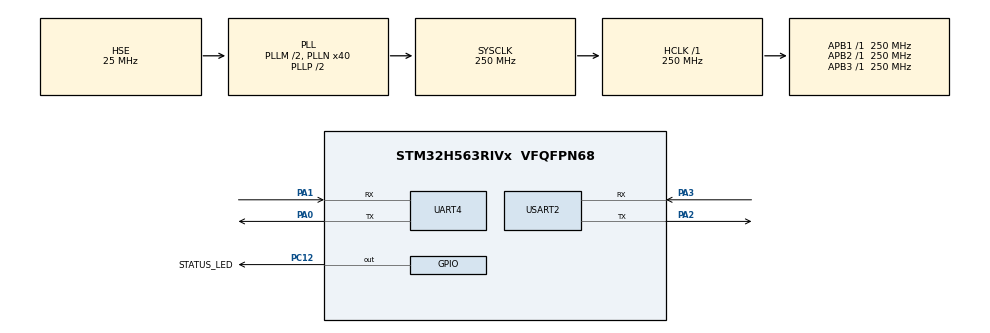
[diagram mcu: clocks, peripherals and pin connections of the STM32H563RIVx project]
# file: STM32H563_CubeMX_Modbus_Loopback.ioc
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BOOTPATH.BootPathName=LEGACY
BOOTPATH.UserSelectedBootPath=LEGACY
CORTEX_M33_NS.MPU_Control.Ext=__NULL
CORTEX_M33_NS.userName=CORTEX_M33
DCACHE1.DCACHE_Read_Burst_Type.Ext=DCACHE_READ_BURST_WRAP
DCACHE1.Instance.Ext=DCACHE$Index
Extended=true
Mcu.Family=STM32H5
Mcu.Name=STM32H563RIVx
Mcu.Package=VFQFPN68
NVIC.PriorityGroup=NVIC_PRIORITYGROUP_4
NVIC.UART4_IRQn=true\:10\:0\:true\:false\:true\:true\:true\:true
NVIC.USART2_IRQn=true\:10\:0\:true\:false\:true\:true\:true\:true
PA0.Mode=Asynchronous
PA0.Signal=UART4_TX
PA1.Mode=Asynchronous
PA1.Signal=UART4_RX
PA2.Mode=Asynchronous
PA2.Signal=USART2_TX
PA3.Mode=Asynchronous
PA3.Signal=USART2_RX
PC12.GPIO_Label=STATUS_LED
PC12.Signal=GPIO_Output
PH0-OSC_IN(PH0).Mode=HSE-External-Oscillator
PH0-OSC_IN(PH0).Signal=RCC_OSC_IN
PH1-OSC_OUT(PH1).Mode=HSE-External-Oscillator
PH1-OSC_OUT(PH1).Signal=RCC_OSC_OUT
PWR.DisableDeadBatterySignalsConfig.Ext=Disable
PWR.pwrPrivilege.Ext=PWR_PRIVILEGE_NO
ProjectManager.HeapSize=0x200
ProjectManager.StackSize=0x400
ProjectManager.TargetToolchain=MDK-ARM V5.37
RCC.ADCCLockSelection.Ext=RCC_ADCDACCLKSOURCE_HCLK
RCC.ADCFreq_Value=250000000
RCC.AHBCLKDivider.Ext=RCC_SYSCLK_DIV1
RCC.AHBCLKDividerARG.Ext=RCC_SYSCLK_DIV1
RCC.AHBFreq_Value=250000000
RCC.APB1CLKDivider.Ext=RCC_HCLK_DIV1
RCC.APB1CLKDividerARG.Ext=RCC_HCLK_DIV1
RCC.APB1Freq_Value=250000000
RCC.APB1TimCLKDivider.Ext=1
RCC.APB1TimFreq_Value=250000000
RCC.APB2CLKDivider.Ext=RCC_HCLK_DIV1
RCC.APB2CLKDividerARG.Ext=RCC_HCLK_DIV1
RCC.APB2Freq_Value=250000000
RCC.APB2TimCLKDivider.Ext=1
RCC.APB2TimFreq_Value=250000000
RCC.APB3Freq_Value=250000000
RCC.CKPERSourceSelection.Ext=RCC_CLKPSOURCE_HSI
RCC.CSICalibrationValue=16
RCC.CSI_VALUE=4000000
RCC.ClockType.Ext=RCC_CLOCKTYPE_HCLK|RCC_CLOCKTYPE_SYSCLK|RCC_CLOCKTYPE_PCLK1|RCC_CLOCKTYPE_PCLK2|RCC_CLOCKTYPE_PCLK3
RCC.ClockTypeARG.Ext=RCC_CLOCKTYPE_HCLK|RCC_CLOCKTYPE_SYSCLK|RCC_CLOCKTYPE_PCLK1|RCC_CLOCKTYPE_PCLK2|RCC_CLOCKTYPE_PCLK3
RCC.ClockTypeHCLK.Ext=RCC_CLOCKTYPE_HCLK
RCC.ClockTypePCLK1.Ext=RCC_CLOCKTYPE_PCLK1
RCC.ClockTypePCLK2.Ext=RCC_CLOCKTYPE_PCLK2
RCC.ClockTypePCLK3.Ext=RCC_CLOCKTYPE_PCLK3
RCC.ClockTypeSysClk.Ext=RCC_CLOCKTYPE_SYSCLK
RCC.CortexFreq_Value=250000000
RCC.Cortex_Div.Ext=SYSTICK_CLKSOURCE_HCLK
RCC.EPOD_VALUE=25000000
RCC.EnableCSSLSE.Ext=false
RCC.EnbaleCSS.Ext=false
RCC.FLatency.Ext=FLASH_LATENCY_5
RCC.Flash_Delay.Ext=FLASH_PROGRAMMING_DELAY_2
RCC.HCLKFreq_Value=250000000
RCC.HSE_Timout.Ext=100
RCC.HSE_VALUE=25000000
RCC.HSI48_VALUE=48000000
RCC.HSICalibrationValue.Ext=64
RCC.HSI_VALUE=64000000
RCC.I2C1CLockSelection.Ext=RCC_I2C1CLKSOURCE_PCLK1
RCC.I2C2CLockSelection.Ext=RCC_I2C2CLKSOURCE_PCLK1
RCC.I2C3CLockSelection.Ext=RCC_I2C3CLKSOURCE_PCLK3
RCC.I3C1CLockSelection.Ext=RCC_I3C1CLKSOURCE_PCLK1
RCC.LPTIM1CLockSelection.Ext=RCC_LPTIM1CLKSOURCE_PCLK3
RCC.LPTIM2CLockSelection.Ext=RCC_LPTIM2CLKSOURCE_PCLK1
RCC.LPUART1CLockSelection.Ext=RCC_LPUART1CLKSOURCE_PCLK3
RCC.LSE_Timout.Ext=5000
RCC.LSE_VALUE=32768
RCC.LSIRC_VALUE=32000
RCC.OscillatorType.Ext=RCC_OSCILLATORTYPE_HSE
RCC.PLL1P.Ext=2
RCC.PLL1Q.Ext=2
RCC.PLL1R.Ext=2
RCC.PLL1_VCI_Range.Ext=RCC_PLL1_VCIRANGE_3
RCC.PLL2FRACN=0
RCC.PLL2M.Ext=1
RCC.PLL2P.Ext=2
RCC.PLL2Q.Ext=2
RCC.PLL2R.Ext=2
RCC.PLL2_VCI_Range.Ext=RCC_PLL2_VCIRANGE_3
RCC.PLL3FRACN=0
RCC.PLL3M.Ext=1
RCC.PLL3P.Ext=2
RCC.PLL3_VCI_Range.Ext=RCC_PLL3_VCIRANGE_3
RCC.PLLFRACN=0
RCC.PLLM=2
RCC.PLLN=40
RCC.PLLSourceVirtual=RCC_PLL1_SOURCE_HSE
RCC.PWR_Regulator_Voltage_Scale.Ext=PWR_REGULATOR_VOLTAGE_SCALE0
RCC.RCC_MCO1Source.Ext=RCC_MCO1SOURCE_HSI
RCC.RCC_MCO2Div.Ext=RCC_MCODIV_1
RCC.RCC_MCODiv.Ext=RCC_MCODIV_1
RCC.RCC_RTC_Clock_Source_FROM_HSE.Ext=RCC_RTC_HSE_NOCLOCK
RCC.RCC_TIM_PRescaler_Selection.Ext=RCC_TIMPRES_DESACTIVATED
RCC.RTCClockSelection.Ext=RCC_RTCCLKSOURCE_LSI
RCC.SAI1CLockSelection.Ext=RCC_SAI1CLKSOURCE_PLL2P
RCC.SAI2CLockSelection.Ext=RCC_SAI2CLKSOURCE_PLL2P
RCC.SDMMC1ClockSelection.Ext=RCC_SDMMC1CLKSOURCE_PLL1Q
RCC.SPI1CLockSelection.Ext=RCC_SPI1CLKSOURCE_PLL1Q
RCC.SPI2CLockSelection.Ext=RCC_SPI2CLKSOURCE_PLL1Q
RCC.SPI3CLockSelection.Ext=RCC_SPI3CLKSOURCE_PLL1Q
RCC.SYSCLKFreq_VALUE=250000000
RCC.SYSCLKSource=RCC_SYSCLKSOURCE_PLLCLK
RCC.SYSCLKSourceARG.Ext=RCC_SYSCLKSOURCE_PLLCLK
RCC.UART4CLockSelection.Ext=RCC_UART4CLKSOURCE_PCLK1
RCC.UART5CLockSelection.Ext=RCC_UART5CLKSOURCE_PCLK1
RCC.USART1CLockSelection.Ext=RCC_USART1CLKSOURCE_PCLK2
RCC.USART2CLockSelection.Ext=RCC_USART2CLKSOURCE_PCLK1
RCC.USART3CLockSelection.Ext=RCC_USART3CLKSOURCE_PCLK1
RCC.USBCLockSelection.Ext=RCC_USBCLKSOURCE_HSI48
RCC.USBFreq_Value=48000000
RCC.VCOOutputFreq_Value=500000000
RCC.VDD_VALUE.Ext=3.3
RCC.rccPrivilegeNSecure.Ext=RCC_NSEC_NPRIV
TIM2.AsymmetricalDeadTime.Ext=DISABLE
TIM2.AutoReloadPreload=TIM_AUTORELOAD_PRELOAD_DISABLE
TIM2.AutoReloadPreload.Ext=TIM_AUTORELOAD_PRELOAD_DISABLE
TIM2.ClockDivision=TIM_CLOCKDIVISION_DIV1
TIM2.ClockDivision.Ext=TIM_CLOCKDIVISION_DIV1
TIM2.CounterMode=TIM_COUNTERMODE_UP
TIM2.CounterMode.Ext=TIM_COUNTERMODE_UP
TIM2.DeadTimePreload.Ext=DISABLE
TIM2.Dithering.Ext=Disable
TIM2.Fractionnal_PeriodDither.Ext=15
TIM2.Integer_PeriodDither.Ext=268435455
TIM2.Period=4294967295
TIM2.PeriodNoDither=4294967295
TIM2.PeriodNoDither.Ext=4294967295
TIM2.Prescaler=249
TIM2.Prescaler.Ext=249
TIM2.PulseWidth.Ext=0
TIM2.PulseWidthPrescaler.Ext=0
TIM2.TIM_MasterOutputTrigger=TIM_TRGO_RESET
TIM2.TIM_MasterOutputTrigger.Ext=TIM_TRGO_RESET
TIM2.TIM_MasterSlaveMode=TIM_MASTERSLAVEMODE_DISABLE
TIM2.TIM_MasterSlaveMode.Ext=TIM_MASTERSLAVEMODE_DISABLE
UART4.AutoBaudRateEnableParam.Ext=UART_ADVFEATURE_AUTOBAUDRATE_DISABLE
UART4.BaudRate.Ext=115200
UART4.ClockPrescaler.Ext=PRESCALER_DIV1
UART4.DMADisableonRxErrorParam.Ext=UART_ADVFEATURE_DMA_ENABLEONRXERROR
UART4.DataInvertParam.Ext=UART_ADVFEATURE_DATAINV_DISABLE
UART4.FIFOMode.Ext=FIFOMODE_DISABLE
UART4.HwFlowCtl.Ext=UART_HWCONTROL_NONE
UART4.MSBFirstParam.Ext=UART_ADVFEATURE_MSBFIRST_DISABLE
UART4.Mode.Ext=MODE_TX_RX
UART4.OneBitSampling.Ext=UART_ONE_BIT_SAMPLE_DISABLE
UART4.OverSampling.Ext=UART_OVERSAMPLING_16
UART4.OverrunDisableParam.Ext=UART_ADVFEATURE_OVERRUN_ENABLE
UART4.Parity.Ext=PARITY_NONE
UART4.RXFIFOThreshold.Ext=RXFIFO_THRESHOLD_1EIGHTHFULL
UART4.RxPinLevelInvertParam.Ext=UART_ADVFEATURE_RXINV_DISABLE
UART4.StopBits.Ext=UART_STOPBITS_1
UART4.SwapParam.Ext=UART_ADVFEATURE_SWAP_DISABLE
UART4.TXFIFOThreshold.Ext=TXFIFO_THRESHOLD_1EIGHTHFULL
UART4.TxPinLevelInvertParam.Ext=UART_ADVFEATURE_TXINV_DISABLE
UART4.VirtualMode-Asynchronous=VM_ASYNC
UART4.WordLength.Ext=WORDLENGTH_8B
USART2.AutoBaudRateEnableParam.Ext=UART_ADVFEATURE_AUTOBAUDRATE_DISABLE
USART2.BaudRate.Ext=115200
USART2.ClockPrescaler.Ext=PRESCALER_DIV1
USART2.DMADisableonRxErrorParam.Ext=ADVFEATURE_DMA_ENABLEONRXERROR
USART2.DataInvertParam.Ext=ADVFEATURE_DATAINV_DISABLE
USART2.FIFOMode.Ext=FIFOMODE_DISABLE
USART2.HwFlowCtl.Ext=UART_HWCONTROL_NONE
USART2.MSBFirstParam.Ext=ADVFEATURE_MSBFIRST_DISABLE
USART2.Mode.Ext=MODE_TX_RX
USART2.OneBitSampling.Ext=UART_ONE_BIT_SAMPLE_DISABLE
USART2.OverSampling.Ext=UART_OVERSAMPLING_16
USART2.OverrunDisableParam.Ext=ADVFEATURE_OVERRUN_ENABLE
USART2.Parity.Ext=PARITY_NONE
USART2.RXFIFOThreshold.Ext=RXFIFO_THRESHOLD_1EIGHTHFULL
USART2.RxPinLevelInvertParam.Ext=ADVFEATURE_RXINV_DISABLE
USART2.StopBits.Ext=STOPBITS_1
USART2.SwapParam.Ext=ADVFEATURE_SWAP_DISABLE
USART2.TXFIFOThreshold.Ext=TXFIFO_THRESHOLD_1EIGHTHFULL
USART2.TxPinLevelInvertParam.Ext=ADVFEATURE_TXINV_DISABLE
USART2.VirtualMode-Asynchronous=VM_ASYNC
USART2.VirtualMode.Ext=VM_ASYNC
USART2.WordLength.Ext=WORDLENGTH_8B
VP_BOOTPATH_VS_BOOTPATH.Mode=BP_Activate
VP_CORTEX_M33_NS_VS_Hclk.Mode=Hclk_Mode
VP_DCACHE1_VS_DCACHE.Mode=DCACHE_Activate
VP_ICACHE_VS_ICACHE.Mode=DefaultMode
VP_MEMORYMAP_VS_MEMORYMAP.Mode=CurAppReg
VP_PWR_VS_DBSignals.Mode=DisableDeadBatterySignals
VP_PWR_VS_LPOM.Mode=PowerOptimisation
VP_PWR_VS_SECSignals.Mode=Security/Privilege
VP_RIF_VS_RIF1.Mode=RISUP
VP_TIM2_VS_ClockSourceINT.Mode=Internal
board=custom

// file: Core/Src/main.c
/* USER CODE BEGIN Header */
/**
  ******************************************************************************
  * @file           : main.c
  * @brief          : Main program body
  ******************************************************************************
  * @attention
  *
  * Copyright (c) 2026 STMicroelectronics.
  * All rights reserved.
  *
  * This software is licensed under terms that can be found in the LICENSE file
  * in the root directory of this software component.
  * If no LICENSE file comes with this software, it is provided AS-IS.
  *
  ******************************************************************************
  */
/* USER CODE END Header */
#include "main.h"
#include "dcache.h"
#include "icache.h"
#include "memorymap.h"
#include "tim.h"
#include "usart.h"
#include "gpio.h"

/* USER CODE BEGIN Includes */
#include "modbus_example.h"

/* USER CODE END Includes */

void SystemClock_Config(void);

int main(void)
{

  /* MCU Configuration--------------------------------------------------------*/

  /* Reset of all peripherals, Initializes the Flash interface and the Systick. */
  HAL_Init();

  /* Configure the system clock */
  SystemClock_Config();

  /* Initialize all configured peripherals */
  MX_GPIO_Init();
  MX_ICACHE_Init();
  MX_DCACHE1_Init();
  MX_UART4_Init();
  MX_USART2_UART_Init();
  MX_TIM2_Init();
  /* USER CODE BEGIN 2 */
  if (modbus_example_init() != HAL_OK)
  {
    Error_Handler();
  }

  /* USER CODE END 2 */

  /* Infinite loop */
  /* USER CODE BEGIN WHILE */
  while (1)
  {
    modbus_example_poll();
    /* USER CODE END WHILE */

  }
}

void SystemClock_Config(void)
{
  RCC_OscInitTypeDef RCC_OscInitStruct = {0};
  RCC_ClkInitTypeDef RCC_ClkInitStruct = {0};

  /** Configure the main internal regulator output voltage
  */
  __HAL_PWR_VOLTAGESCALING_CONFIG(PWR_REGULATOR_VOLTAGE_SCALE0);

  while(!__HAL_PWR_GET_FLAG(PWR_FLAG_VOSRDY)) {}

  /** Initializes the RCC Oscillators according to the specified parameters
  * in the RCC_OscInitTypeDef structure.
  */
  RCC_OscInitStruct.OscillatorType = RCC_OSCILLATORTYPE_HSE;
  RCC_OscInitStruct.HSEState = RCC_HSE_ON;
  RCC_OscInitStruct.PLL.PLLState = RCC_PLL_ON;
  RCC_OscInitStruct.PLL.PLLSource = RCC_PLL1_SOURCE_HSE;
  RCC_OscInitStruct.PLL.PLLM = 2;
  RCC_OscInitStruct.PLL.PLLN = 40;
  RCC_OscInitStruct.PLL.PLLP = 2;
  RCC_OscInitStruct.PLL.PLLQ = 2;
  RCC_OscInitStruct.PLL.PLLR = 2;
  RCC_OscInitStruct.PLL.PLLRGE = RCC_PLL1_VCIRANGE_3;
  RCC_OscInitStruct.PLL.PLLVCOSEL = RCC_PLL1_VCORANGE_WIDE;
  RCC_OscInitStruct.PLL.PLLFRACN = 0;
  if (HAL_RCC_OscConfig(&RCC_OscInitStruct) != HAL_OK)
  {
    Error_Handler();
  }

  /** Initializes the CPU, AHB and APB buses clocks
  */
  RCC_ClkInitStruct.ClockType = RCC_CLOCKTYPE_HCLK|RCC_CLOCKTYPE_SYSCLK
                              |RCC_CLOCKTYPE_PCLK1|RCC_CLOCKTYPE_PCLK2
                              |RCC_CLOCKTYPE_PCLK3;
  RCC_ClkInitStruct.SYSCLKSource = RCC_SYSCLKSOURCE_PLLCLK;
  RCC_ClkInitStruct.AHBCLKDivider = RCC_SYSCLK_DIV1;
  RCC_ClkInitStruct.APB1CLKDivider = RCC_HCLK_DIV1;
  RCC_ClkInitStruct.APB2CLKDivider = RCC_HCLK_DIV1;
  RCC_ClkInitStruct.APB3CLKDivider = RCC_HCLK_DIV1;

  if (HAL_RCC_ClockConfig(&RCC_ClkInitStruct, FLASH_LATENCY_5) != HAL_OK)
  {
    Error_Handler();
  }

  /** Configure the programming delay
  */
  __HAL_FLASH_SET_PROGRAM_DELAY(FLASH_PROGRAMMING_DELAY_2);
}

void Error_Handler(void)
{
  __disable_irq();
  while (1)
  {
  }
}
